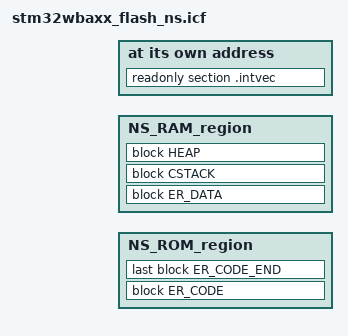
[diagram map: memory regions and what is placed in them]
/*###ICF### Section handled by ICF editor, don't touch! ****/
/*-Editor annotation file-*/
/* IcfEditorFile="$TOOLKIT_DIR$\config\ide\IcfEditor\cortex_v1_0.xml" */
/*-Specials-*/
/*************************************************************************************************/
#include "loader_region_defs.h"

/*************************************************************************************************/
/*-Memory Regions-*/
define symbol __ICFEDIT_region_ROM_start__ = LOADER_NS_CODE_START;
define symbol __ICFEDIT_region_ROM_end__   = (LOADER_NS_CODE_START + LOADER_NS_CODE_SIZE - 1);
define symbol __ICFEDIT_region_RAM_start__ = LOADER_NS_DATA_START;
define symbol __ICFEDIT_region_RAM_end__   = (LOADER_NS_DATA_START + LOADER_NS_DATA_SIZE - 1);

/*-Sizes-*/
define symbol __ICFEDIT_size_cstack__ = LOADER_NS_MSP_STACK_SIZE;
define symbol __ICFEDIT_size_heap__ = LOADER_NS_HEAP_SIZE;
/**** End of ICF editor section. ###ICF###*/

define memory mem with size = 4G;

define region NS_ROM_region =   mem:[from __ICFEDIT_region_ROM_start__ to __ICFEDIT_region_ROM_end__];
define region NS_RAM_region  =  mem:[from __ICFEDIT_region_RAM_start__ to __ICFEDIT_region_RAM_end__];

define block CSTACK    with alignment = 8, size = __ICFEDIT_size_cstack__   { };
define block HEAP      with alignment = 8, size = __ICFEDIT_size_heap__     { };


define block ER_CODE		with alignment = 8 {readonly};
define block ER_CODE_END with alignment = 32, size = 0 { };

place at address mem:LOADER_NS_CODE_START { readonly section .intvec };
define block ER_DATA with maximum size = 0x10000, alignment = 8 {readwrite};

do not initialize  { section .noinit };
initialize by copy { readwrite };
if (isdefinedsymbol(__USE_DLIB_PERTHREAD))
{
  // Required in a multi-threaded application
  initialize by copy with packing = none { section __DLIB_PERTHREAD };
}

place in NS_ROM_region  { block ER_CODE , last block ER_CODE_END,};
place in NS_RAM_region   { block ER_DATA, block CSTACK, block HEAP };
